AUTOSAR XML (schema 00043)
package /ara/diag
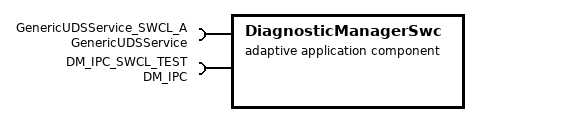
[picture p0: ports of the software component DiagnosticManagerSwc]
  adaptive application sw component type DiagnosticManagerSwc
    require port GenericUDSService_SWCL_A: required-interface=GenericUDSService
    require port DM_IPC_SWCL_TEST: required-interface=DM_IPC
